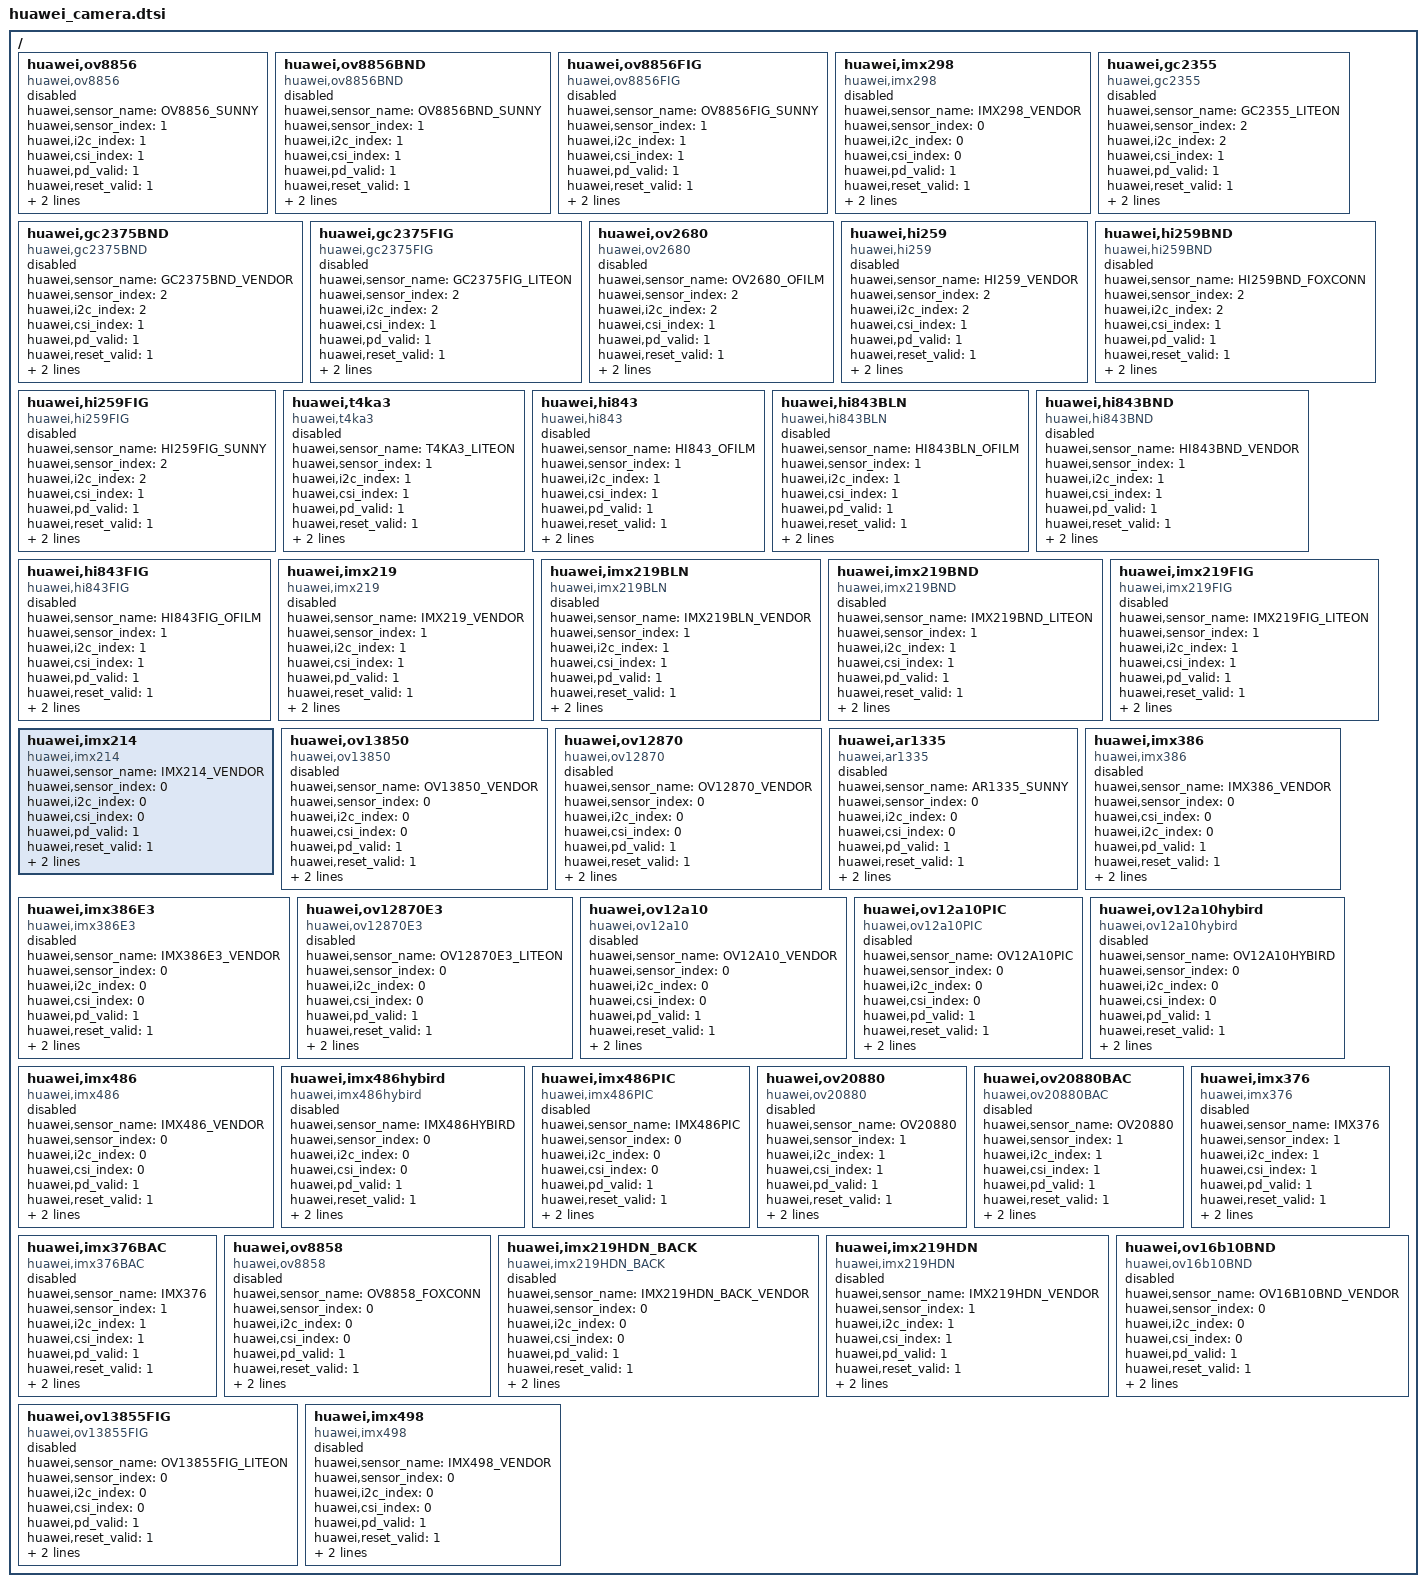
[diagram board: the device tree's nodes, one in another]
/*
  Camera sensor driver dtsi setting, which are used by PUD3 products and HISI UDP
*/

 /{
        huawei,ov8856 {
                compatible = "huawei,ov8856";
                huawei,sensor_name = "OV8856_SUNNY";
                huawei,sensor_index = <1>;
                huawei,i2c_index = <1>;
                huawei,csi_index = <1>;
                huawei,pd_valid = <1>;
                huawei,reset_valid = <1>;
                huawei,vcmpd_valid = <0>;

        hisi,is_fpga = <0>;
                status = "disabled";
        };

        huawei,ov8856BND {
                compatible = "huawei,ov8856BND";
                huawei,sensor_name = "OV8856BND_SUNNY";
                huawei,sensor_index = <1>;
                huawei,i2c_index = <1>;
                huawei,csi_index = <1>;
                huawei,pd_valid = <1>;
                huawei,reset_valid = <1>;
                huawei,vcmpd_valid = <0>;

        hisi,is_fpga = <0>;
                status = "disabled";
        };

        huawei,ov8856FIG {
                compatible = "huawei,ov8856FIG";
                huawei,sensor_name = "OV8856FIG_SUNNY";
                huawei,sensor_index = <1>;
                huawei,i2c_index = <1>;
                huawei,csi_index = <1>;
                huawei,pd_valid = <1>;
                huawei,reset_valid = <1>;
                huawei,vcmpd_valid = <0>;

        hisi,is_fpga = <0>;
                status = "disabled";
        };

        huawei,imx298 {
                compatible = "huawei,imx298";
                huawei,sensor_name = "IMX298_VENDOR";
                huawei,sensor_index = <0>;
                huawei,i2c_index = <0>;
                huawei,csi_index = <0>;
                huawei,pd_valid = <1>;
                huawei,reset_valid = <1>;
                huawei,vcmpd_valid = <0>;

        hisi,is_fpga = <0>;
                status = "disabled";
        };
        
        huawei,gc2355 {
                compatible = "huawei,gc2355";
                huawei,sensor_name = "GC2355_LITEON";
                huawei,sensor_index = <2>;
                huawei,i2c_index = <2>;
                huawei,csi_index = <1>;
                huawei,pd_valid = <1>;
                huawei,reset_valid = <1>;
                huawei,vcmpd_valid = <0>;

                hisi,is_fpga = <0>;
                status = "disabled";
        };

        huawei,gc2375BND {
                compatible = "huawei,gc2375BND";
                huawei,sensor_name = "GC2375BND_VENDOR";
                huawei,sensor_index = <2>;
                huawei,i2c_index = <2>;
                huawei,csi_index = <1>;
                huawei,pd_valid = <1>;
                huawei,reset_valid = <1>;
                huawei,vcmpd_valid = <0>;

                hisi,is_fpga = <0>;
                status = "disabled";
        };

        huawei,gc2375FIG {
                compatible = "huawei,gc2375FIG";
                huawei,sensor_name = "GC2375FIG_LITEON";
                huawei,sensor_index = <2>;
                huawei,i2c_index = <2>;
                huawei,csi_index = <1>;
                huawei,pd_valid = <1>;
                huawei,reset_valid = <1>;
                huawei,vcmpd_valid = <0>;

                hisi,is_fpga = <0>;
                status = "disabled";
        };

	huawei,ov2680 {
                compatible = "huawei,ov2680";
                huawei,sensor_name = "OV2680_OFILM";
                huawei,sensor_index = <2>;
                huawei,i2c_index = <2>;
                huawei,csi_index = <1>;
                huawei,pd_valid = <1>;
                huawei,reset_valid = <1>;
                huawei,vcmpd_valid = <0>;

                hisi,is_fpga = <0>;
                status = "disabled";
        };

        huawei,hi259 {
                compatible = "huawei,hi259";
                huawei,sensor_name = "HI259_VENDOR";
                huawei,sensor_index = <2>;
                huawei,i2c_index = <2>;
                huawei,csi_index = <1>;
                huawei,pd_valid = <1>;
                huawei,reset_valid = <1>;
                huawei,vcmpd_valid = <0>;

                hisi,is_fpga = <0>;
                status = "disabled";
        };

        huawei,hi259BND {
                compatible = "huawei,hi259BND";
                huawei,sensor_name = "HI259BND_FOXCONN";
                huawei,sensor_index = <2>;
                huawei,i2c_index = <2>;
                huawei,csi_index = <1>;
                huawei,pd_valid = <1>;
                huawei,reset_valid = <1>;
                huawei,vcmpd_valid = <0>;

                hisi,is_fpga = <0>;
                status = "disabled";
        };


        huawei,hi259FIG {
                compatible = "huawei,hi259FIG";
                huawei,sensor_name = "HI259FIG_SUNNY";
                huawei,sensor_index = <2>;
                huawei,i2c_index = <2>;
                huawei,csi_index = <1>;
                huawei,pd_valid = <1>;
                huawei,reset_valid = <1>;
                huawei,vcmpd_valid = <0>;

                hisi,is_fpga = <0>;
                status = "disabled";
        };

	huawei,t4ka3 {
		compatible = "huawei,t4ka3";
		huawei,sensor_name = "T4KA3_LITEON";
		huawei,sensor_index = <1>;
		huawei,i2c_index = <1>;
		huawei,csi_index = <1>;
		huawei,pd_valid = <1>;
		huawei,reset_valid = <1>;
		huawei,vcmpd_valid = <0>;

		hisi,is_fpga = <0>;
		status = "disabled";
	};

        huawei,hi843 {
                compatible = "huawei,hi843";
                huawei,sensor_name = "HI843_OFILM";
                huawei,sensor_index = <1>;
                huawei,i2c_index = <1>;
                huawei,csi_index = <1>;
                huawei,pd_valid = <1>;
                huawei,reset_valid = <1>;
                huawei,vcmpd_valid = <0>;

        hisi,is_fpga = <0>;
                status = "disabled";
        };

	huawei,hi843BLN {
                compatible = "huawei,hi843BLN";
                huawei,sensor_name = "HI843BLN_OFILM";
                huawei,sensor_index = <1>;
                huawei,i2c_index = <1>;
                huawei,csi_index = <1>;
                huawei,pd_valid = <1>;
                huawei,reset_valid = <1>;
                huawei,vcmpd_valid = <0>;

        hisi,is_fpga = <0>;
                status = "disabled";
        };

	huawei,hi843BND {
                compatible = "huawei,hi843BND";
                huawei,sensor_name = "HI843BND_VENDOR";
                huawei,sensor_index = <1>;
                huawei,i2c_index = <1>;
                huawei,csi_index = <1>;
                huawei,pd_valid = <1>;
                huawei,reset_valid = <1>;
                huawei,vcmpd_valid = <0>;

        hisi,is_fpga = <0>;
                status = "disabled";
        };

    huawei,hi843FIG {
                compatible = "huawei,hi843FIG";
                huawei,sensor_name = "HI843FIG_OFILM";
                huawei,sensor_index = <1>;
                huawei,i2c_index = <1>;
                huawei,csi_index = <1>;
                huawei,pd_valid = <1>;
                huawei,reset_valid = <1>;
                huawei,vcmpd_valid = <0>;

        hisi,is_fpga = <0>;
                status = "disabled";
        };

    huawei,imx219 {
                compatible = "huawei,imx219";
                huawei,sensor_name = "IMX219_VENDOR";
                huawei,sensor_index = <1>;
                huawei,i2c_index = <1>;
                huawei,csi_index = <1>;
                huawei,pd_valid = <1>;
                huawei,reset_valid = <1>;
                huawei,vcmpd_valid = <0>;

        hisi,is_fpga = <0>;
                status = "disabled";
    };

	huawei,imx219BLN {
                compatible = "huawei,imx219BLN";
                huawei,sensor_name = "IMX219BLN_VENDOR";
                huawei,sensor_index = <1>;
                huawei,i2c_index = <1>;
                huawei,csi_index = <1>;
                huawei,pd_valid = <1>;
                huawei,reset_valid = <1>;
                huawei,vcmpd_valid = <0>;

        hisi,is_fpga = <0>;
                status = "disabled";
    };

    huawei,imx219BND {
                compatible = "huawei,imx219BND";
                huawei,sensor_name = "IMX219BND_LITEON";
                huawei,sensor_index = <1>;
                huawei,i2c_index = <1>;
                huawei,csi_index = <1>;
                huawei,pd_valid = <1>;
                huawei,reset_valid = <1>;
                huawei,vcmpd_valid = <0>;

        hisi,is_fpga = <0>;
                status = "disabled";
    };

    huawei,imx219FIG {
                compatible = "huawei,imx219FIG";
                huawei,sensor_name = "IMX219FIG_LITEON";
                huawei,sensor_index = <1>;
                huawei,i2c_index = <1>;
                huawei,csi_index = <1>;
                huawei,pd_valid = <1>;
                huawei,reset_valid = <1>;
                huawei,vcmpd_valid = <0>;

        hisi,is_fpga = <0>;
                status = "disabled";
    };

	huawei,imx214 {
		compatible = "huawei,imx214";
		huawei,sensor_name = "IMX214_VENDOR";
		huawei,sensor_index = <0>;
		huawei,i2c_index = <0>;
		huawei,csi_index = <0>;
		huawei,pd_valid = <1>;
		huawei,reset_valid = <1>;
		huawei,vcmpd_valid = <0>;

        hisi,is_fpga = <1>;
		status = "ok";
	};

	huawei,ov13850 {
		compatible = "huawei,ov13850";
		huawei,sensor_name = "OV13850_VENDOR";
		huawei,sensor_index = <0>;
		huawei,i2c_index = <0>;
		huawei,csi_index = <0>;
		huawei,pd_valid = <1>;
		huawei,reset_valid = <1>;
		huawei,vcmpd_valid = <0>;

        hisi,is_fpga = <0>;
		status = "disabled";
	};

	huawei,ov12870 {
		compatible = "huawei,ov12870";
		huawei,sensor_name = "OV12870_VENDOR";
		huawei,sensor_index = <0>;
		huawei,i2c_index = <0>;
		huawei,csi_index = <0>;
		huawei,pd_valid = <1>;
		huawei,reset_valid = <1>;
		huawei,vcmpd_valid = <0>;

        hisi,is_fpga = <0>;
		status = "disabled";
	};

	huawei,ar1335 {
		compatible = "huawei,ar1335";
		huawei,sensor_name = "AR1335_SUNNY";
		huawei,sensor_index = <0>;
		huawei,i2c_index = <0>;
		huawei,csi_index = <0>;
		huawei,pd_valid = <1>;
		huawei,reset_valid = <1>;
		huawei,vcmpd_valid = <0>;

        hisi,is_fpga = <0>;
		status = "disabled";
	};
	
    huawei,imx386 {
        compatible = "huawei,imx386";
        huawei,sensor_name = "IMX386_VENDOR";
        huawei,sensor_index = <0>;
        huawei,csi_index = <0>;
        huawei,i2c_index = <0>;
        huawei,pd_valid = <1>;
        huawei,reset_valid = <1>;
        huawei,vcmpd_valid = <0>;

        hisi,is_fpga = <0>;
		status = "disabled";
	};

	huawei,imx386E3 {
		compatible = "huawei,imx386E3";
		huawei,sensor_name = "IMX386E3_VENDOR";
		huawei,sensor_index = <0>;
		huawei,i2c_index = <0>;
		huawei,csi_index = <0>;
		huawei,pd_valid = <1>;
		huawei,reset_valid = <1>;
		huawei,vcmpd_valid = <0>;

        hisi,is_fpga = <0>;
		status = "disabled";
	};

	huawei,ov12870E3 {
		compatible = "huawei,ov12870E3";
		huawei,sensor_name = "OV12870E3_LITEON";
		huawei,sensor_index = <0>;
		huawei,i2c_index = <0>;
		huawei,csi_index = <0>;
		huawei,pd_valid = <1>;
		huawei,reset_valid = <1>;
		huawei,vcmpd_valid = <0>;

        hisi,is_fpga = <0>;
		status = "disabled";
	};

	huawei,ov12a10 {
		compatible = "huawei,ov12a10";
		huawei,sensor_name = "OV12A10_VENDOR";
		huawei,sensor_index = <0>;
		huawei,i2c_index = <0>;
		huawei,csi_index = <0>;
		huawei,pd_valid = <1>;
		huawei,reset_valid = <1>;
		huawei,vcmpd_valid = <0>;

		hisi,is_fpga = <0>;
		status = "disabled";
	};

	huawei,ov12a10PIC {
		compatible = "huawei,ov12a10PIC";
		huawei,sensor_name = "OV12A10PIC";
		huawei,sensor_index = <0>;
		huawei,i2c_index = <0>;
		huawei,csi_index = <0>;
		huawei,pd_valid = <1>;
		huawei,reset_valid = <1>;
		huawei,vcmpd_valid = <0>;

		hisi,is_fpga = <0>;
		status = "disabled";
	};

	huawei,ov12a10hybird {
		compatible = "huawei,ov12a10hybird";
		huawei,sensor_name = "OV12A10HYBIRD";
		huawei,sensor_index = <0>;
		huawei,i2c_index = <0>;
		huawei,csi_index = <0>;
		huawei,pd_valid = <1>;
		huawei,reset_valid = <1>;
		huawei,vcmpd_valid = <0>;

		hisi,is_fpga = <0>;
		status = "disabled";
	};
	huawei,imx486 {
		compatible = "huawei,imx486";
		huawei,sensor_name = "IMX486_VENDOR";
		huawei,sensor_index = <0>;
		huawei,i2c_index = <0>;
		huawei,csi_index = <0>;
		huawei,pd_valid = <1>;
		huawei,reset_valid = <1>;
		huawei,vcmpd_valid = <0>;

		hisi,is_fpga = <0>;
		status = "disabled";
	};

	huawei,imx486hybird {
		compatible = "huawei,imx486hybird";
		huawei,sensor_name = "IMX486HYBIRD";
		huawei,sensor_index = <0>;
		huawei,i2c_index = <0>;
		huawei,csi_index = <0>;
		huawei,pd_valid = <1>;
		huawei,reset_valid = <1>;
		huawei,vcmpd_valid = <0>;

		hisi,is_fpga = <0>;
		status = "disabled";
	};

	huawei,imx486PIC {
		compatible = "huawei,imx486PIC";
		huawei,sensor_name = "IMX486PIC";
		huawei,sensor_index = <0>;
		huawei,i2c_index = <0>;
		huawei,csi_index = <0>;
		huawei,pd_valid = <1>;
		huawei,reset_valid = <1>;
		huawei,vcmpd_valid = <0>;

		hisi,is_fpga = <0>;
		status = "disabled";
	};

	huawei,ov20880 {
		compatible = "huawei,ov20880";
		huawei,sensor_name = "OV20880";
		huawei,sensor_index = <1>;
		huawei,i2c_index = <1>;
		huawei,csi_index = <1>;
		huawei,pd_valid = <1>;
		huawei,reset_valid = <1>;
		huawei,vcmpd_valid = <0>;

		hisi,is_fpga = <0>;
		status = "disabled";
	};

	huawei,ov20880BAC {
		compatible = "huawei,ov20880BAC";
		huawei,sensor_name = "OV20880";
		huawei,sensor_index = <1>;
		huawei,i2c_index = <1>;
		huawei,csi_index = <1>;
		huawei,pd_valid = <1>;
		huawei,reset_valid = <1>;
		huawei,vcmpd_valid = <0>;

		hisi,is_fpga = <0>;
		status = "disabled";
	};

	huawei,imx376 {
		compatible = "huawei,imx376";
		huawei,sensor_name = "IMX376";
		huawei,sensor_index = <1>;
		huawei,i2c_index = <1>;
		huawei,csi_index = <1>;
		huawei,pd_valid = <1>;
		huawei,reset_valid = <1>;
		huawei,vcmpd_valid = <0>;

		hisi,is_fpga = <0>;
		status = "disabled";
	};

	huawei,imx376BAC {
		compatible = "huawei,imx376BAC";
		huawei,sensor_name = "IMX376";
		huawei,sensor_index = <1>;
		huawei,i2c_index = <1>;
		huawei,csi_index = <1>;
		huawei,pd_valid = <1>;
		huawei,reset_valid = <1>;
		huawei,vcmpd_valid = <0>;

		hisi,is_fpga = <0>;
		status = "disabled";
	};
	
	huawei,ov8858 {
		compatible = "huawei,ov8858";
		huawei,sensor_name = "OV8858_FOXCONN";
		huawei,sensor_index = <0>;
		huawei,i2c_index = <0>;
		huawei,csi_index = <0>;
		huawei,pd_valid = <1>;
		huawei,reset_valid = <1>;
		huawei,vcmpd_valid = <0>;

		hisi,is_fpga = <0>;
		status = "disabled";
	};

	huawei,imx219HDN_BACK {
		compatible = "huawei,imx219HDN_BACK";
		huawei,sensor_name = "IMX219HDN_BACK_VENDOR";
		huawei,sensor_index = <0>;
		huawei,i2c_index = <0>;
		huawei,csi_index = <0>;
		huawei,pd_valid = <1>;
		huawei,reset_valid = <1>;
		huawei,vcmpd_valid = <0>;

		hisi,is_fpga = <0>;
		status = "disabled";
	};

	huawei,imx219HDN {
		compatible = "huawei,imx219HDN";
		huawei,sensor_name = "IMX219HDN_VENDOR";
		huawei,sensor_index = <1>;
		huawei,i2c_index = <1>;
		huawei,csi_index = <1>;
		huawei,pd_valid = <1>;
		huawei,reset_valid = <1>;
		huawei,vcmpd_valid = <0>;

        hisi,is_fpga = <0>;
		status = "disabled";
	};

    huawei,ov16b10BND {
        compatible = "huawei,ov16b10BND";
        huawei,sensor_name = "OV16B10BND_VENDOR";
        huawei,sensor_index = <0>;
        huawei,i2c_index = <0>;
        huawei,csi_index = <0>;
        huawei,pd_valid = <1>;
        huawei,reset_valid = <1>;
        huawei,vcmpd_valid = <0>;

        hisi,is_fpga = <0>;
        status = "disabled";
    };
    huawei,ov13855FIG {
        compatible = "huawei,ov13855FIG";
        huawei,sensor_name = "OV13855FIG_LITEON";
        huawei,sensor_index = <0>;
        huawei,i2c_index = <0>;
        huawei,csi_index = <0>;
        huawei,pd_valid = <1>;
        huawei,reset_valid = <1>;
        huawei,vcmpd_valid = <0>;

        hisi,is_fpga = <0>;
        status = "disabled";
    };

    huawei,imx498 {
        compatible = "huawei,imx498";
        huawei,sensor_name = "IMX498_VENDOR";
        huawei,sensor_index = <0>;
        huawei,i2c_index = <0>;
        huawei,csi_index = <0>;
        huawei,pd_valid = <1>;
        huawei,reset_valid = <1>;
        huawei,vcmpd_valid = <0>;

        hisi,is_fpga = <0>;
        status = "disabled";
    };
};
